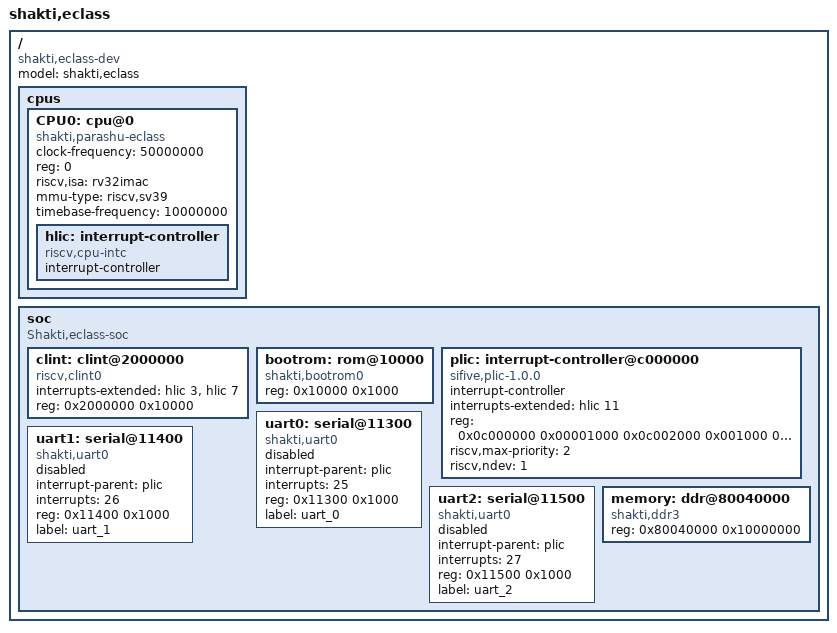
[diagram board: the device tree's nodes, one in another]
#include <dt-bindings/gpio/gpio.h>

/ {
	#address-cells = <1>;
	#size-cells = <1>;
	compatible = "shakti,eclass-dev", "eclass-dev", "shakti-dev";
	model = "shakti,eclass";
	cpus {
		#address-cells = <1>;
		#size-cells = <0>;
		CPU0: cpu@0 {
			clock-frequency = <50000000>;
			compatible = "shakti,parashu-eclass","riscv";
			device_type = "cpu";
			reg = <0>;
			riscv,isa = "rv32imac";
			status = "okay";
			mmu-type = "riscv,sv39";
			timebase-frequency = <10000000>;
			hlic: interrupt-controller {
				#interrupt-cells = <1>;
				compatible = "riscv,cpu-intc";
				interrupt-controller;
			};
		};
	};
	soc {
		#address-cells = <1>;
		#size-cells = <1>;
		compatible = "Shakti,eclass-soc", "eclass-soc",
			"shakti-soc", "simple-bus";
		ranges;
		clint: clint@2000000 {
			compatible = "riscv,clint0";
			interrupts-extended = <&hlic 3 &hlic 7>;
			reg = <0x2000000 0x10000>;
			reg-names = "control";
		};


		bootrom: rom@10000 {
			compatible = "shakti,bootrom0";
			reg = <0x10000 0x1000>;
			reg-names = "mem";
		};
		plic: interrupt-controller@c000000 {
			#interrupt-cells = <1>;
			compatible = "sifive,plic-1.0.0";
			interrupt-controller;
			interrupts-extended = <&hlic 11>;
			reg = <0x0c000000 0x00001000
			       0x0c002000 0x001000
			       0x0c010000 0x0200000>;
			reg-names = "prio", "irq_en", "reg";
			riscv,max-priority = <2>;
			riscv,ndev = <1>;
		};
		uart0: serial@11300 {
			compatible = "shakti,uart0";
			interrupt-parent = <&plic>;
			interrupts = <25>;
			reg= <0x11300 0x1000>;
			reg-names = "control";
			label = "uart_0";
			status = "disabled";
		};
		uart1: serial@11400 {
			compatible = "shakti,uart0";
			interrupt-parent = <&plic>;
			interrupts = <26>;
			reg= <0x11400 0x1000>;
			reg-names = "control";
			label = "uart_1";
			status = "disabled";
		};
		uart2: serial@11500 {
			compatible = "shakti,uart0";
			interrupt-parent = <&plic>;
			interrupts = <27>;
			reg= <0x11500 0x1000>;
			reg-names = "control";
			label = "uart_2";
			status = "disabled";
		};
		memory: ddr@80040000 {
			compatible = "shakti,ddr3";
			reg = <0x80040000 0x10000000>;
		};
	};
};
